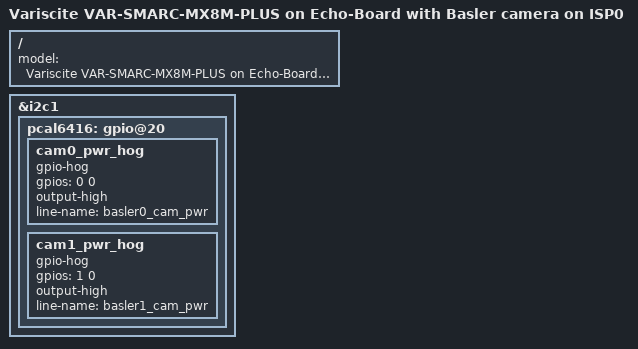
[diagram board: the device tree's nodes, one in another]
// SPDX-License-Identifier: (GPL-2.0+ OR MIT)
/*
 * Copyright 2019 NXP
 * Copyright 2020-2025 Variscite Ltd.
 */

#include "imx8mp-var-smarc-echo.dts"
#include "imx8mp-var-smarc-echo-basler-isp0.dtsi"

/ {
	model = "Variscite VAR-SMARC-MX8M-PLUS on Echo-Board with Basler camera on ISP0";
};

&i2c1 {
	pcal6416: gpio@20 {
		cam0_pwr_hog {
			gpio-hog;
			gpios = <0 0>;
			output-high;
			line-name = "basler0_cam_pwr";
		};
		cam1_pwr_hog {
			gpio-hog;
			gpios = <1 0>;
			output-high;
			line-name = "basler1_cam_pwr";
		};
	};
};
